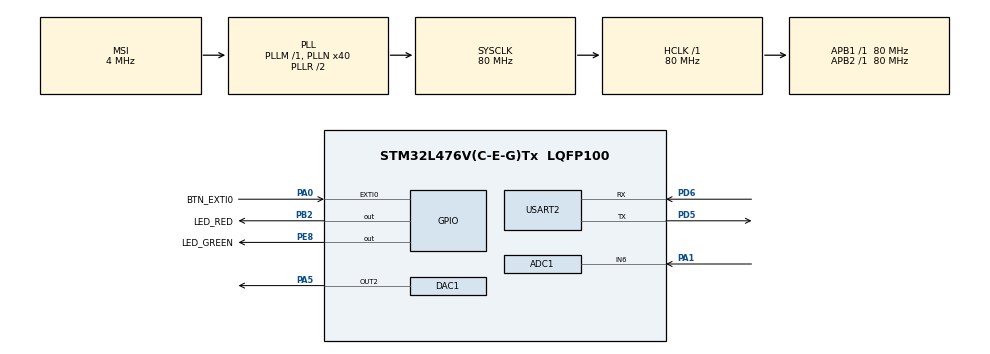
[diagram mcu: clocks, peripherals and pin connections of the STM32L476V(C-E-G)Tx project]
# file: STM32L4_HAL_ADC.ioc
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ADC1.Channel-0\#ChannelRegularConversion=ADC_CHANNEL_6
ADC1.DMAContinuousRequests=ENABLE
ADC1.NbrOfConversionFlag=1
ADC1.OffsetNumber-0\#ChannelRegularConversion=ADC_OFFSET_NONE
ADC1.Rank-0\#ChannelRegularConversion=1
ADC1.SamplingTime-0\#ChannelRegularConversion=ADC_SAMPLETIME_92CYCLES_5
ADC1.master=1
DAC1.DAC_Channel-DAC_OUT2=DAC_CHANNEL_2
Dma.ADC1.0.Direction=DMA_PERIPH_TO_MEMORY
Dma.ADC1.0.Instance=DMA1_Channel1
Dma.ADC1.0.MemDataAlignment=DMA_MDATAALIGN_HALFWORD
Dma.ADC1.0.MemInc=DMA_MINC_ENABLE
Dma.ADC1.0.Mode=DMA_CIRCULAR
Dma.ADC1.0.PeriphDataAlignment=DMA_PDATAALIGN_HALFWORD
Dma.ADC1.0.PeriphInc=DMA_PINC_DISABLE
Dma.ADC1.0.Priority=DMA_PRIORITY_LOW
Dma.Request0=ADC1
Mcu.Family=STM32L4
Mcu.Name=STM32L476V(C-E-G)Tx
Mcu.Package=LQFP100
NVIC.DMA1_Channel1_IRQn=true\:0\:0\:false\:false\:true\:false\:true\:true
NVIC.EXTI0_IRQn=true\:0\:0\:false\:false\:true\:true\:true\:true
NVIC.PriorityGroup=NVIC_PRIORITYGROUP_4
PA0.GPIO_Label=BTN_EXTI0
PA0.Signal=GPXTI0
PA1.Signal=ADCx_IN6
PA13\ (JTMS-SWDIO).Mode=Serial_Wire
PA13\ (JTMS-SWDIO).Signal=SYS_JTMS-SWDIO
PA14\ (JTCK-SWCLK).Mode=Serial_Wire
PA14\ (JTCK-SWCLK).Signal=SYS_JTCK-SWCLK
PA5.Signal=COMP_DAC12_group
PB2.GPIO_Label=LED_RED
PB2.Signal=GPIO_Output
PC14-OSC32_IN\ (PC14).Mode=LSE-External-Oscillator
PC14-OSC32_IN\ (PC14).Signal=RCC_OSC32_IN
PC15-OSC32_OUT\ (PC15).Mode=LSE-External-Oscillator
PC15-OSC32_OUT\ (PC15).Signal=RCC_OSC32_OUT
PD5.Mode=Asynchronous
PD5.Signal=USART2_TX
PD6.Mode=Asynchronous
PD6.Signal=USART2_RX
PE8.GPIO_Label=LED_GREEN
PE8.Signal=GPIO_Output
ProjectManager.HeapSize=0x200
ProjectManager.StackSize=0x400
ProjectManager.TargetToolchain=STM32CubeIDE
RCC.ADCFreq_Value=48000000
RCC.AHBFreq_Value=80000000
RCC.APB1Freq_Value=80000000
RCC.APB1TimFreq_Value=80000000
RCC.APB2Freq_Value=80000000
RCC.APB2TimFreq_Value=80000000
RCC.CortexFreq_Value=80000000
RCC.HCLKFreq_Value=80000000
RCC.HSE_VALUE=8000000
RCC.HSI_VALUE=16000000
RCC.MSI_VALUE=4000000
RCC.PLLN=40
RCC.PLLSAI1N=24
RCC.SYSCLKFreq_VALUE=80000000
RCC.SYSCLKSource=RCC_SYSCLKSOURCE_PLLCLK
RCC.USBFreq_Value=48000000
RCC.VCOOutputFreq_Value=160000000
SH.ADCx_IN6.0=ADC1_IN6,IN6-Single-Ended
SH.COMP_DAC12_group.0=DAC1_OUT2,DAC_OUT2
USART2.VirtualMode-Asynchronous=VM_ASYNC
board=STM32L476G-DISCO

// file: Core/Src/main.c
/* USER CODE BEGIN Header */
/**
  ******************************************************************************
  * @file           : main.c
  * @brief          : Main program body
  ******************************************************************************
  * @attention
  *
  * Copyright (c) 2023 STMicroelectronics.
  * All rights reserved.
  *
  * This software is licensed under terms that can be found in the LICENSE file
  * in the root directory of this software component.
  * If no LICENSE file comes with this software, it is provided AS-IS.
  *
  ******************************************************************************
  */
/* USER CODE END Header */
#include "main.h"
#include "adc.h"
#include "dac.h"
#include "dma.h"
#include "usart.h"
#include "gpio.h"

void SystemClock_Config(void);

/* USER CODE BEGIN 0 */

uint16_t adcVal;
uint16_t dacVal = 0;

/* USER CODE END 0 */

int main(void)
{

  /* MCU Configuration--------------------------------------------------------*/

  /* Reset of all peripherals, Initializes the Flash interface and the Systick. */
  HAL_Init();

  /* Configure the system clock */
  SystemClock_Config();

  /* Initialize all configured peripherals */
  MX_GPIO_Init();
  MX_DMA_Init();
  MX_USART2_UART_Init();
  MX_DAC1_Init();
  MX_ADC1_Init();
  /* USER CODE BEGIN 2 */

  // ADC calibration & start
  HAL_ADCEx_Calibration_Start(&hadc1, ADC_SINGLE_ENDED);
  HAL_ADC_Start_DMA(&hadc1, (uint32_t *)&adcVal, 1);

  // DAC start
  HAL_DAC_Start(&hdac1, DAC_CHANNEL_2);

  /* USER CODE END 2 */

  /* Infinite loop */
  while (1)
  {

    /* USER CODE BEGIN 3 */

    // connect PA1 & PA5 pins to measure DAC output by ADC
    HAL_DAC_SetValue(&hdac1, DAC_CHANNEL_2, DAC_ALIGN_12B_R, dacVal);
    if(dacVal < 4095)
    {
      dacVal++;
    }
    else
    {
      dacVal = 0;
    }

    HAL_Delay(10);
    HAL_ADC_Start(&hadc1);
  }
  /* USER CODE END 3 */
}

void SystemClock_Config(void)
{
  RCC_OscInitTypeDef RCC_OscInitStruct = {0};
  RCC_ClkInitTypeDef RCC_ClkInitStruct = {0};

  /** Configure the main internal regulator output voltage
  */
  if (HAL_PWREx_ControlVoltageScaling(PWR_REGULATOR_VOLTAGE_SCALE1) != HAL_OK)
  {
    Error_Handler();
  }

  /** Configure LSE Drive Capability
  */
  HAL_PWR_EnableBkUpAccess();
  __HAL_RCC_LSEDRIVE_CONFIG(RCC_LSEDRIVE_LOW);

  /** Initializes the RCC Oscillators according to the specified parameters
  * in the RCC_OscInitTypeDef structure.
  */
  RCC_OscInitStruct.OscillatorType = RCC_OSCILLATORTYPE_LSE|RCC_OSCILLATORTYPE_MSI;
  RCC_OscInitStruct.LSEState = RCC_LSE_ON;
  RCC_OscInitStruct.MSIState = RCC_MSI_ON;
  RCC_OscInitStruct.MSICalibrationValue = 0;
  RCC_OscInitStruct.MSIClockRange = RCC_MSIRANGE_6;
  RCC_OscInitStruct.PLL.PLLState = RCC_PLL_ON;
  RCC_OscInitStruct.PLL.PLLSource = RCC_PLLSOURCE_MSI;
  RCC_OscInitStruct.PLL.PLLM = 1;
  RCC_OscInitStruct.PLL.PLLN = 40;
  RCC_OscInitStruct.PLL.PLLP = RCC_PLLP_DIV7;
  RCC_OscInitStruct.PLL.PLLQ = RCC_PLLQ_DIV2;
  RCC_OscInitStruct.PLL.PLLR = RCC_PLLR_DIV2;
  if (HAL_RCC_OscConfig(&RCC_OscInitStruct) != HAL_OK)
  {
    Error_Handler();
  }

  /** Initializes the CPU, AHB and APB buses clocks
  */
  RCC_ClkInitStruct.ClockType = RCC_CLOCKTYPE_HCLK|RCC_CLOCKTYPE_SYSCLK
                              |RCC_CLOCKTYPE_PCLK1|RCC_CLOCKTYPE_PCLK2;
  RCC_ClkInitStruct.SYSCLKSource = RCC_SYSCLKSOURCE_PLLCLK;
  RCC_ClkInitStruct.AHBCLKDivider = RCC_SYSCLK_DIV1;
  RCC_ClkInitStruct.APB1CLKDivider = RCC_HCLK_DIV1;
  RCC_ClkInitStruct.APB2CLKDivider = RCC_HCLK_DIV1;

  if (HAL_RCC_ClockConfig(&RCC_ClkInitStruct, FLASH_LATENCY_4) != HAL_OK)
  {
    Error_Handler();
  }

  /** Enable MSI Auto calibration
  */
  HAL_RCCEx_EnableMSIPLLMode();
}

void Error_Handler(void)
{
  __disable_irq();
  while (1)
  {
  }
}
